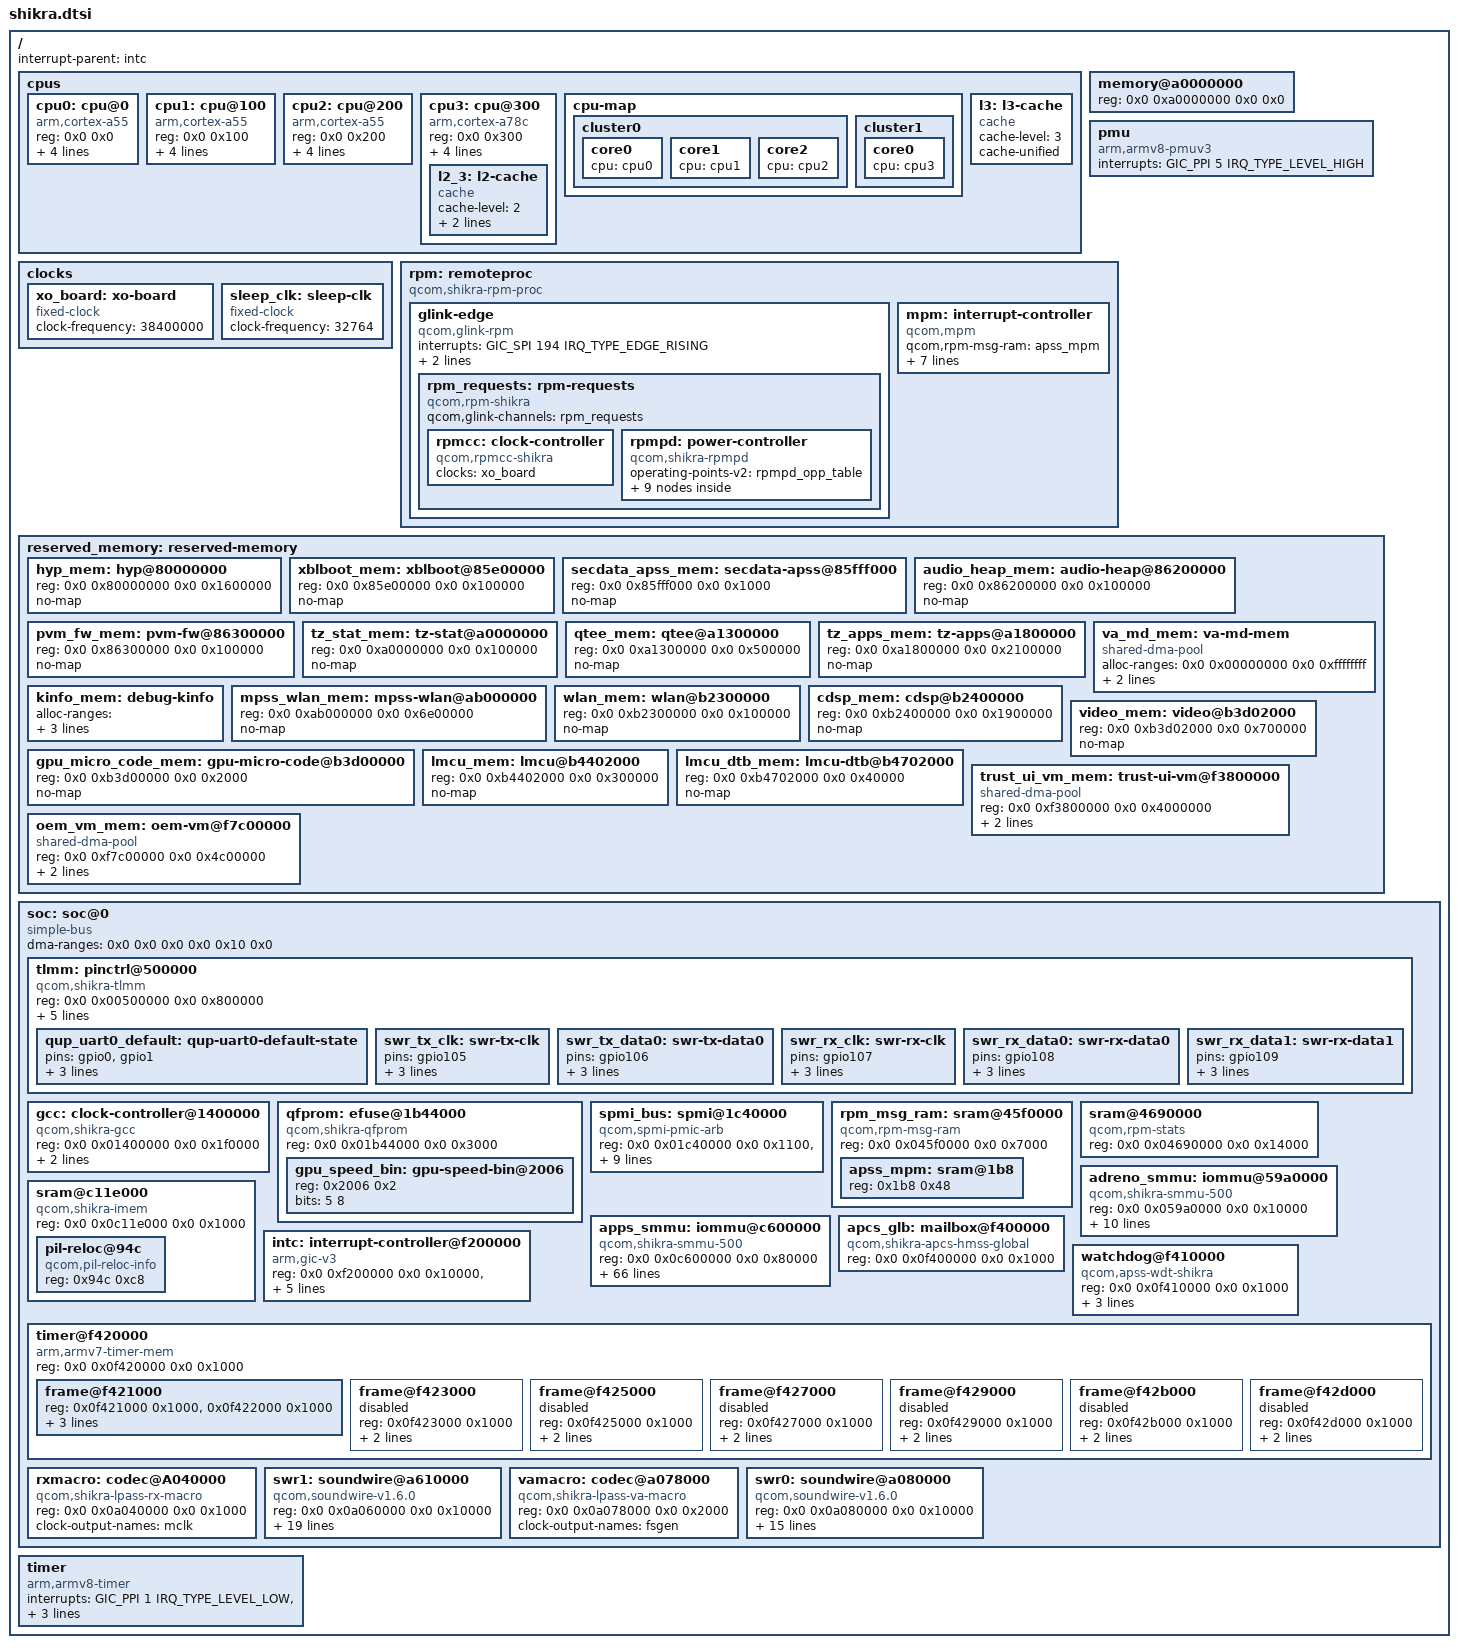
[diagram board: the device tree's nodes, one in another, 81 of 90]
// SPDX-License-Identifier: BSD-3-Clause
/*
 * Copyright (c) Qualcomm Technologies, Inc. and/or its subsidiaries.
 */

#include <dt-bindings/clock/qcom,rpmcc.h>
#include <dt-bindings/power/qcom-rpmpd.h>
#include <dt-bindings/clock/qcom,shikra-gcc.h>
#include <dt-bindings/interrupt-controller/arm-gic.h>
#include <dt-bindings/soc/qcom,gpr.h>
#include <dt-bindings/sound/qcom,q6dsp-lpass-ports.h>

/ {
	interrupt-parent = <&intc>;

	#address-cells = <2>;
	#size-cells = <2>;

	cpus {
		#address-cells = <2>;
		#size-cells = <0>;

		cpu0: cpu@0 {
			device_type = "cpu";
			compatible = "arm,cortex-a55";
			reg = <0x0 0x0>;
			enable-method = "psci";
			next-level-cache = <&l3>;
			capacity-dmips-mhz = <1024>;
			dynamic-power-coefficient = <100>;
		};

		cpu1: cpu@100 {
			device_type = "cpu";
			compatible = "arm,cortex-a55";
			reg = <0x0 0x100>;
			enable-method = "psci";
			next-level-cache = <&l3>;
			capacity-dmips-mhz = <1024>;
			dynamic-power-coefficient = <100>;
		};

		cpu2: cpu@200 {
			device_type = "cpu";
			compatible = "arm,cortex-a55";
			reg = <0x0 0x200>;
			enable-method = "psci";
			next-level-cache = <&l3>;
			capacity-dmips-mhz = <1024>;
			dynamic-power-coefficient = <100>;
		};

		cpu3: cpu@300 {
			device_type = "cpu";
			compatible = "arm,cortex-a78c";
			reg = <0x0 0x300>;
			enable-method = "psci";
			next-level-cache = <&l2_3>;
			capacity-dmips-mhz = <1946>;
			dynamic-power-coefficient = <486>;

			l2_3: l2-cache {
				compatible = "cache";
				cache-level = <2>;
				cache-unified;
				next-level-cache = <&l3>;
			};
		};

		cpu-map {
			cluster0 {
				core0 {
					cpu = <&cpu0>;
				};

				core1 {
					cpu = <&cpu1>;
				};

				core2 {
					cpu = <&cpu2>;
				};
			};

			cluster1 {
				core0 {
					cpu = <&cpu3>;
				};
			};
		};

		l3: l3-cache {
			compatible = "cache";
			cache-level = <3>;
			cache-unified;
		};
	};

	clocks {
		xo_board: xo-board {
			compatible = "fixed-clock";
			clock-frequency = <38400000>;
			#clock-cells = <0>;
		};

		sleep_clk: sleep-clk {
			compatible = "fixed-clock";
			clock-frequency = <32764>;
			#clock-cells = <0>;
		};
	};

	memory@a0000000 {
		device_type = "memory";
		/* We expect the bootloader to fill in the size */
		reg = <0x0 0xa0000000 0x0 0x0>;
	};

	pmu {
		compatible = "arm,armv8-pmuv3";
		interrupts = <GIC_PPI 5 IRQ_TYPE_LEVEL_HIGH>;
	};

	rpm: remoteproc {
		compatible = "qcom,shikra-rpm-proc", "qcom,rpm-proc";

		glink-edge {
			compatible = "qcom,glink-rpm";
			interrupts = <GIC_SPI 194 IRQ_TYPE_EDGE_RISING>;
			qcom,rpm-msg-ram = <&rpm_msg_ram>;
			mboxes = <&apcs_glb 0>;

			rpm_requests: rpm-requests {
				compatible = "qcom,rpm-shikra", "qcom,glink-smd-rpm";
				qcom,glink-channels = "rpm_requests";

				rpmcc: clock-controller {
					compatible = "qcom,rpmcc-shikra", "qcom,rpmcc";
					clocks = <&xo_board>;
					clock-names = "xo";
					#clock-cells = <1>;
				};

				rpmpd: power-controller {
					compatible = "qcom,shikra-rpmpd";
					#power-domain-cells = <1>;
					operating-points-v2 = <&rpmpd_opp_table>;

					rpmpd_opp_table: opp-table {
						compatible = "operating-points-v2";

						rpmpd_opp_min_svs: opp1 {
							opp-level = <RPM_SMD_LEVEL_MIN_SVS>;
						};

						rpmpd_opp_low_svs: opp2 {
							opp-level = <RPM_SMD_LEVEL_LOW_SVS>;
						};

						rpmpd_opp_svs: opp3 {
							opp-level = <RPM_SMD_LEVEL_SVS>;
						};

						rpmpd_opp_svs_plus: opp4 {
							opp-level = <RPM_SMD_LEVEL_SVS_PLUS>;
						};

						rpmpd_opp_nom: opp5 {
							opp-level = <RPM_SMD_LEVEL_NOM>;
						};

						rpmpd_opp_nom_plus: opp6 {
							opp-level = <RPM_SMD_LEVEL_NOM_PLUS>;
						};

						rpmpd_opp_turbo: opp7 {
							opp-level = <RPM_SMD_LEVEL_TURBO>;
						};

						rpmpd_opp_turbo_plus: opp8 {
							opp-level = <RPM_SMD_LEVEL_TURBO_NO_CPR>;
						};
					};
				};
			};
		};

		mpm: interrupt-controller {
			compatible = "qcom,mpm";
			qcom,rpm-msg-ram = <&apss_mpm>;
			interrupts = <GIC_SPI 197 IRQ_TYPE_EDGE_RISING>;
			mboxes = <&apcs_glb 1>;
			interrupt-controller;
			#interrupt-cells = <2>;
			#power-domain-cells = <0>;
			interrupt-parent = <&intc>;
			qcom,mpm-pin-count = <95>;
			qcom,mpm-pin-map = <2 275>,  /* TSENS0 uplow */
					   <12 422>, /* DWC3 ss_phy_irq */
					   <58 272>, /* QUSB2_PHY dmse_hv_vddmx */
					   <59 273>, /* QUSB2_PHY dpse_hv_vddmx */
					   <86 183>, /* MPM wake, SPMI */
					   <90 157>, /* QUSB2_PHY DM */
					   <91 158>; /* QUSB2_PHY DP */
		};
	};

	reserved_memory: reserved-memory {
		#address-cells = <2>;
		#size-cells = <2>;
		ranges;

		hyp_mem: hyp@80000000 {
			reg = <0x0 0x80000000 0x0 0x1600000>;
			no-map;
		};

		xblboot_mem: xblboot@85e00000 {
			reg = <0x0 0x85e00000 0x0 0x100000>;
			no-map;
		};

		secdata_apss_mem: secdata-apss@85fff000 {
			reg = <0x0 0x85fff000 0x0 0x1000>;
			no-map;
		};

		audio_heap_mem: audio-heap@86200000 {
			reg = <0x0 0x86200000 0x0 0x100000>;
			no-map;
		};

		pvm_fw_mem: pvm-fw@86300000 {
			reg = <0x0 0x86300000 0x0 0x100000>;
			no-map;
		};

		/* UEFI region at 0x9F400000 is reclaimed by Linux */
		tz_stat_mem: tz-stat@a0000000 {
			reg = <0x0 0xa0000000 0x0 0x100000>;
			no-map;
		};

		qtee_mem: qtee@a1300000 {
			reg = <0x0 0xa1300000 0x0 0x500000>;
			no-map;
		};

		tz_apps_mem: tz-apps@a1800000 {
			reg = <0x0 0xa1800000 0x0 0x2100000>;
			no-map;
		};

		va_md_mem: va-md-mem {
			compatible = "shared-dma-pool";
			alloc-ranges = <0x0 0x00000000 0x0 0xffffffff>;
			size = <0x0 0x1000000>;
			reusable;
		};

		kinfo_mem: debug-kinfo {
			alloc-ranges = <0x0 0x00000000 0xffffffff 0xffffffff>;
			size = <0x0 0x1000>;
			no-map;
		};

		mpss_wlan_mem: mpss-wlan@ab000000 {
			reg = <0x0 0xab000000 0x0 0x6e00000>;
			no-map;
		};

		wlan_mem: wlan@b2300000 {
			reg = <0x0 0xb2300000 0x0 0x100000>;
			no-map;
		};

		cdsp_mem: cdsp@b2400000 {
			reg = <0x0 0xb2400000 0x0 0x1900000>;
			no-map;
		};

		gpu_micro_code_mem: gpu-micro-code@b3d00000 {
			reg = <0x0 0xb3d00000 0x0 0x2000>;
			no-map;
		};

		video_mem: video@b3d02000 {
			reg = <0x0 0xb3d02000 0x0 0x700000>;
			no-map;
		};

		lmcu_mem: lmcu@b4402000 {
			reg = <0x0 0xb4402000 0x0 0x300000>;
			no-map;
		};

		lmcu_dtb_mem: lmcu-dtb@b4702000 {
			reg = <0x0 0xb4702000 0x0 0x40000>;
			no-map;
		};

		/* Linux kernel image is loaded at 0xB5000000 */
		trust_ui_vm_mem: trust-ui-vm@f3800000 {
			compatible = "shared-dma-pool";
			reg = <0x0 0xf3800000 0x0 0x4000000>;
			alignment = <0x0 0x400000>;
			reusable;
		};

		oem_vm_mem: oem-vm@f7c00000 {
			compatible = "shared-dma-pool";
			reg = <0x0 0xf7c00000 0x0 0x4c00000>;
			alignment = <0x0 0x400000>;
			reusable;
		};
	};

	soc: soc@0 {
		compatible = "simple-bus";

		#address-cells = <2>;
		#size-cells = <2>;
		dma-ranges = <0x0 0x0 0x0 0x0 0x10 0x0>;
		ranges = <0x0 0x0 0x0 0x0 0x10 0x0>;

		tlmm: pinctrl@500000 {
			compatible = "qcom,shikra-tlmm";
			reg = <0x0 0x00500000 0x0 0x800000>;

			interrupts = <GIC_SPI 227 IRQ_TYPE_LEVEL_HIGH>;

			gpio-controller;
			#gpio-cells = <2>;

			interrupt-controller;
			#interrupt-cells = <2>;

			gpio-ranges = <&tlmm 0 0 185>;
			wakeup-parent = <&mpm>;

			qup_uart0_default: qup-uart0-default-state {
				pins = "gpio0", "gpio1";
				function = "qup0_se1";
				drive-strength = <2>;
				bias-disable;
			};

			swr_tx_clk: swr-tx-clk {
				pins = "gpio105";
				function = "swr0_tx_clk";
				drive-strength = <10>;
				bias-disable;
			};

			swr_tx_data0: swr-tx-data0 {
				pins = "gpio106";
				function = "swr0_tx_data0";
				drive-strength = <10>;
				bias-bus-hold;
			};

			swr_rx_clk: swr-rx-clk {
				pins = "gpio107";
                                function = "swr0_rx_clk";
                                drive-strength = <10>;
                                bias-disable;
                        };

                        swr_rx_data0: swr-rx-data0 {
				pins = "gpio108";
                                function = "swr0_rx_data0";
                                drive-strength = <10>;
                                bias-bus-hold;
                        };

                        swr_rx_data1: swr-rx-data1 {
				pins = "gpio109";
                                function = "swr0_rx_data1";
                                drive-strength = <10>;
                                bias-bus-hold;
                        };
		};

		gcc: clock-controller@1400000 {
			compatible = "qcom,shikra-gcc";
			reg = <0x0 0x01400000 0x0 0x1f0000>;
			clocks = <&rpmcc RPM_SMD_XO_CLK_SRC>,
				 <&sleep_clk>,
				 <0>,
				 <0>,
				 <0>,
				 <0>,
				 <0>,
				 <0>;
			#clock-cells = <1>;
			#reset-cells = <1>;
			#power-domain-cells = <1>;
		};

		qfprom: efuse@1b44000 {
			compatible = "qcom,shikra-qfprom", "qcom,qfprom";
			reg = <0x0 0x01b44000 0x0 0x3000>;
			#address-cells = <1>;
			#size-cells = <1>;

			gpu_speed_bin: gpu-speed-bin@2006 {
				reg = <0x2006 0x2>;
				bits = <5 8>;
			};
		};

		spmi_bus: spmi@1c40000 {
			compatible = "qcom,spmi-pmic-arb";
			reg = <0x0 0x01c40000 0x0 0x1100>,
			      <0x0 0x01e00000 0x0 0x2000000>,
			      <0x0 0x03e00000 0x0 0x100000>,
			      <0x0 0x03f00000 0x0 0xa0000>,
			      <0x0 0x01c0a000 0x0 0x26000>;
			reg-names = "core",
				    "chnls",
				    "obsrvr",
				    "intr",
				    "cnfg";
			interrupts-extended = <&mpm 86 IRQ_TYPE_LEVEL_HIGH>;
			interrupt-names = "periph_irq";
			interrupt-controller;
			#interrupt-cells = <4>;
			#address-cells = <2>;
			#size-cells = <0>;
			qcom,channel = <0>;
			qcom,ee = <0>;
		};

		rpm_msg_ram: sram@45f0000 {
			compatible = "qcom,rpm-msg-ram", "mmio-sram";
			reg = <0x0 0x045f0000 0x0 0x7000>;

			#address-cells = <1>;
			#size-cells = <1>;
			ranges = <0 0x0 0x045f0000 0x7000>;

			apss_mpm: sram@1b8 {
				reg = <0x1b8 0x48>;
			};
		};

		sram@4690000 {
			compatible = "qcom,rpm-stats";
			reg = <0x0 0x04690000 0x0 0x14000>;
		};

		adreno_smmu: iommu@59a0000 {
			compatible = "qcom,shikra-smmu-500", "qcom,smmu-500", "arm,mmu-500";
			reg = <0x0 0x059a0000 0x0 0x10000>;
			#iommu-cells = <2>;
			#global-interrupts = <1>;

			interrupts = <GIC_SPI 163 IRQ_TYPE_LEVEL_HIGH>,
				     <GIC_SPI 167 IRQ_TYPE_LEVEL_HIGH>,
				     <GIC_SPI 168 IRQ_TYPE_LEVEL_HIGH>,
				     <GIC_SPI 169 IRQ_TYPE_LEVEL_HIGH>,
				     <GIC_SPI 170 IRQ_TYPE_LEVEL_HIGH>,
				     <GIC_SPI 171 IRQ_TYPE_LEVEL_HIGH>,
				     <GIC_SPI 172 IRQ_TYPE_LEVEL_HIGH>,
				     <GIC_SPI 173 IRQ_TYPE_LEVEL_HIGH>,
				     <GIC_SPI 174 IRQ_TYPE_LEVEL_HIGH>;
		};

		sram@c11e000 {
			compatible = "qcom,shikra-imem", "syscon", "simple-mfd";
			reg = <0x0 0x0c11e000 0x0 0x1000>;
			ranges = <0x0 0x0 0x0c11e000 0x1000>;

			#address-cells = <1>;
			#size-cells = <1>;

			pil-reloc@94c {
				compatible = "qcom,pil-reloc-info";
				reg = <0x94c 0xc8>;
			};
		};

		apps_smmu: iommu@c600000 {
			compatible = "qcom,shikra-smmu-500", "qcom,adreno-smmu",
				     "qcom,smmu-500", "arm,mmu-500";
			reg = <0x0 0x0c600000 0x0 0x80000>;
			#iommu-cells = <2>;
			#global-interrupts = <1>;

			interrupts = <GIC_SPI 81 IRQ_TYPE_LEVEL_HIGH>,
				     <GIC_SPI 87 IRQ_TYPE_LEVEL_HIGH>,
				     <GIC_SPI 88 IRQ_TYPE_LEVEL_HIGH>,
				     <GIC_SPI 89 IRQ_TYPE_LEVEL_HIGH>,
				     <GIC_SPI 90 IRQ_TYPE_LEVEL_HIGH>,
				     <GIC_SPI 91 IRQ_TYPE_LEVEL_HIGH>,
				     <GIC_SPI 92 IRQ_TYPE_LEVEL_HIGH>,
				     <GIC_SPI 93 IRQ_TYPE_LEVEL_HIGH>,
				     <GIC_SPI 94 IRQ_TYPE_LEVEL_HIGH>,
				     <GIC_SPI 95 IRQ_TYPE_LEVEL_HIGH>,
				     <GIC_SPI 96 IRQ_TYPE_LEVEL_HIGH>,
				     <GIC_SPI 97 IRQ_TYPE_LEVEL_HIGH>,
				     <GIC_SPI 98 IRQ_TYPE_LEVEL_HIGH>,
				     <GIC_SPI 99 IRQ_TYPE_LEVEL_HIGH>,
				     <GIC_SPI 100 IRQ_TYPE_LEVEL_HIGH>,
				     <GIC_SPI 101 IRQ_TYPE_LEVEL_HIGH>,
				     <GIC_SPI 102 IRQ_TYPE_LEVEL_HIGH>,
				     <GIC_SPI 103 IRQ_TYPE_LEVEL_HIGH>,
				     <GIC_SPI 104 IRQ_TYPE_LEVEL_HIGH>,
				     <GIC_SPI 105 IRQ_TYPE_LEVEL_HIGH>,
				     <GIC_SPI 106 IRQ_TYPE_LEVEL_HIGH>,
				     <GIC_SPI 107 IRQ_TYPE_LEVEL_HIGH>,
				     <GIC_SPI 108 IRQ_TYPE_LEVEL_HIGH>,
				     <GIC_SPI 109 IRQ_TYPE_LEVEL_HIGH>,
				     <GIC_SPI 110 IRQ_TYPE_LEVEL_HIGH>,
				     <GIC_SPI 111 IRQ_TYPE_LEVEL_HIGH>,
				     <GIC_SPI 112 IRQ_TYPE_LEVEL_HIGH>,
				     <GIC_SPI 113 IRQ_TYPE_LEVEL_HIGH>,
				     <GIC_SPI 114 IRQ_TYPE_LEVEL_HIGH>,
				     <GIC_SPI 115 IRQ_TYPE_LEVEL_HIGH>,
				     <GIC_SPI 116 IRQ_TYPE_LEVEL_HIGH>,
				     <GIC_SPI 117 IRQ_TYPE_LEVEL_HIGH>,
				     <GIC_SPI 118 IRQ_TYPE_LEVEL_HIGH>,
				     <GIC_SPI 119 IRQ_TYPE_LEVEL_HIGH>,
				     <GIC_SPI 120 IRQ_TYPE_LEVEL_HIGH>,
				     <GIC_SPI 121 IRQ_TYPE_LEVEL_HIGH>,
				     <GIC_SPI 122 IRQ_TYPE_LEVEL_HIGH>,
				     <GIC_SPI 123 IRQ_TYPE_LEVEL_HIGH>,
				     <GIC_SPI 124 IRQ_TYPE_LEVEL_HIGH>,
				     <GIC_SPI 125 IRQ_TYPE_LEVEL_HIGH>,
				     <GIC_SPI 126 IRQ_TYPE_LEVEL_HIGH>,
				     <GIC_SPI 127 IRQ_TYPE_LEVEL_HIGH>,
				     <GIC_SPI 128 IRQ_TYPE_LEVEL_HIGH>,
				     <GIC_SPI 129 IRQ_TYPE_LEVEL_HIGH>,
				     <GIC_SPI 130 IRQ_TYPE_LEVEL_HIGH>,
				     <GIC_SPI 131 IRQ_TYPE_LEVEL_HIGH>,
				     <GIC_SPI 132 IRQ_TYPE_LEVEL_HIGH>,
				     <GIC_SPI 133 IRQ_TYPE_LEVEL_HIGH>,
				     <GIC_SPI 134 IRQ_TYPE_LEVEL_HIGH>,
				     <GIC_SPI 135 IRQ_TYPE_LEVEL_HIGH>,
				     <GIC_SPI 136 IRQ_TYPE_LEVEL_HIGH>,
				     <GIC_SPI 137 IRQ_TYPE_LEVEL_HIGH>,
				     <GIC_SPI 138 IRQ_TYPE_LEVEL_HIGH>,
				     <GIC_SPI 139 IRQ_TYPE_LEVEL_HIGH>,
				     <GIC_SPI 140 IRQ_TYPE_LEVEL_HIGH>,
				     <GIC_SPI 141 IRQ_TYPE_LEVEL_HIGH>,
				     <GIC_SPI 142 IRQ_TYPE_LEVEL_HIGH>,
				     <GIC_SPI 143 IRQ_TYPE_LEVEL_HIGH>,
				     <GIC_SPI 144 IRQ_TYPE_LEVEL_HIGH>,
				     <GIC_SPI 145 IRQ_TYPE_LEVEL_HIGH>,
				     <GIC_SPI 146 IRQ_TYPE_LEVEL_HIGH>,
				     <GIC_SPI 147 IRQ_TYPE_LEVEL_HIGH>,
				     <GIC_SPI 148 IRQ_TYPE_LEVEL_HIGH>,
				     <GIC_SPI 149 IRQ_TYPE_LEVEL_HIGH>,
				     <GIC_SPI 150 IRQ_TYPE_LEVEL_HIGH>;
		};

		intc: interrupt-controller@f200000 {
			compatible = "arm,gic-v3";
			reg = <0x0 0xf200000 0x0 0x10000>, /* GICD */
			      <0x0 0xf240000 0x0 0x80000>; /* GICR * 4 regions */

			interrupts = <GIC_PPI 8 IRQ_TYPE_LEVEL_HIGH>;

			#interrupt-cells = <3>;
			interrupt-controller;

			#redistributor-regions = <1>;
			redistributor-stride = <0x0 0x20000>;

			#address-cells = <2>;
			#size-cells = <2>;
			ranges;
		};

		apcs_glb: mailbox@f400000 {
			compatible = "qcom,shikra-apcs-hmss-global";
			reg = <0x0 0x0f400000 0x0 0x1000>;
			#mbox-cells = <1>;
		};

		watchdog@f410000 {
			compatible = "qcom,apss-wdt-shikra", "qcom,kpss-wdt";
			reg = <0x0 0x0f410000 0x0 0x1000>;
			interrupts = <GIC_SPI 0 IRQ_TYPE_LEVEL_HIGH>,
				     <GIC_SPI 1 IRQ_TYPE_LEVEL_HIGH>;
			clocks = <&sleep_clk>;
		};

		timer@f420000 {
			compatible = "arm,armv7-timer-mem";
			reg = <0x0 0x0f420000  0x0 0x1000>;

			#address-cells = <1>;
			#size-cells = <1>;
			ranges = <0x0 0x0 0x0 0x10000000>;

			frame@f421000 {
				reg = <0x0f421000 0x1000>,
				      <0x0f422000 0x1000>;
				frame-number = <0>;
				interrupts = <GIC_SPI 8 IRQ_TYPE_LEVEL_HIGH>,
					     <GIC_SPI 6 IRQ_TYPE_LEVEL_HIGH>;
			};

			frame@f423000 {
				reg = <0x0f423000 0x1000>;
				frame-number = <1>;
				interrupts = <GIC_SPI 9 IRQ_TYPE_LEVEL_HIGH>;
				status = "disabled";
			};

			frame@f425000 {
				reg = <0x0f425000 0x1000>;
				frame-number = <2>;
				interrupts = <GIC_SPI 10 IRQ_TYPE_LEVEL_HIGH>;
				status = "disabled";
			};

			frame@f427000 {
				reg = <0x0f427000 0x1000>;
				frame-number = <3>;
				interrupts = <GIC_SPI 11 IRQ_TYPE_LEVEL_HIGH>;
				status = "disabled";
			};

			frame@f429000 {
				reg = <0x0f429000 0x1000>;
				frame-number = <4>;
				interrupts = <GIC_SPI 12 IRQ_TYPE_LEVEL_HIGH>;
				status = "disabled";
			};

			frame@f42b000 {
				reg = <0x0f42b000 0x1000>;
				frame-number = <5>;
				interrupts = <GIC_SPI 13 IRQ_TYPE_LEVEL_HIGH>;
				status = "disabled";
			};

			frame@f42d000 {
				reg = <0x0f42d000 0x1000>;
				frame-number = <6>;
				interrupts = <GIC_SPI 14 IRQ_TYPE_LEVEL_HIGH>;
				status = "disabled";
			};
		};


		rxmacro: codec@A040000 {
			compatible = "qcom,shikra-lpass-rx-macro";
			reg = <0x0 0x0a040000 0x0 0x1000>;

			/* TODO: once Gpr and prm enbled enble below clocks */
			//clocks = <&q6prmcc LPASS_CLK_ID_RX_CORE_MCLK LPASS_CLK_ATTRIBUTE_COUPLE_NO>,
			//	 <&q6prmcc LPASS_CLK_ID_RX_CORE_NPL_MCLK LPASS_CLK_ATTRIBUTE_COUPLE_NO>,
			//	 <&q6prmcc LPASS_HW_DCODEC_VOTE LPASS_CLK_ATTRIBUTE_COUPLE_NO>,
			//	 <&vamacro>;
			//clock-names = "mclk",
			//	      "npl",
			//	      "dcodec",
			//	      "fsgen";
			#clock-cells = <0>;
			clock-output-names = "mclk";
			#sound-dai-cells = <1>;
		};

		swr1: soundwire@a610000 {
			compatible = "qcom,soundwire-v1.6.0";
			reg = <0x0 0x0a060000 0x0 0x10000>;
			interrupts = <GIC_SPI 330 IRQ_TYPE_LEVEL_HIGH>;

			clocks = <&rxmacro>;
			clock-names = "iface";

			label = "RX";
			qcom,din-ports = <0>;
			qcom,dout-ports = <5>;

			qcom,ports-sinterval-low =	/bits/ 8 <0x03 0x1f 0x1f 0x07 0x00>;
			qcom,ports-offset1 =		/bits/ 8 <0x00 0x00 0x0b 0x01 0x00>;
			qcom,ports-offset2 =		/bits/ 8 <0x00 0x00 0x0b 0x00 0x00>;
			qcom,ports-hstart =		/bits/ 8 <0xff 0x03 0xff 0xff 0xff>;
			qcom,ports-hstop =		/bits/ 8 <0xff 0x06 0xff 0xff 0xff>;
			qcom,ports-word-length =	/bits/ 8 <0x01 0x07 0x04 0xff 0xff>;
			qcom,ports-block-pack-mode =	/bits/ 8 <0xff 0x00 0x01 0xff 0xff>;
			qcom,ports-block-group-count =	/bits/ 8 <0xff 0xff 0xff 0xff 0x00>;
			qcom,ports-lane-control =	/bits/ 8 <0x01 0x00 0x00 0x00 0x00>;

			#sound-dai-cells = <1>;
			#address-cells = <2>;
			#size-cells = <0>;
		};


		vamacro: codec@a078000 {
			compatible = "qcom,shikra-lpass-va-macro";
			reg = <0x0 0x0a078000 0x0 0x2000>;

			/* TODO: once Gpr and prm enbled enble below clocks */
			//clocks = <&q6prmcc LPASS_CLK_ID_TX_CORE_MCLK LPASS_CLK_ATTRIBUTE_COUPLE_NO>,
			//	 <&q6prmcc LPASS_HW_DCODEC_VOTE LPASS_CLK_ATTRIBUTE_COUPLE_NO>,
			//	 <&q6prmcc LPASS_CLK_ID_TX_CORE_NPL_MCLK LPASS_CLK_ATTRIBUTE_COUPLE_NO>;
			//clock-names = "mclk",
			//	      "dcodec",
			//	      "npl";
			#clock-cells = <0>;
			clock-output-names = "fsgen";
			#sound-dai-cells = <1>;
		};

		swr0: soundwire@a080000 {
			compatible = "qcom,soundwire-v1.6.0";
			reg = <0x0 0x0a080000 0x0 0x10000>;
			interrupts = <GIC_SPI 328 IRQ_TYPE_LEVEL_HIGH>,
				     <GIC_SPI 406 IRQ_TYPE_LEVEL_HIGH>;
			clocks = <&vamacro>;
			clock-names = "iface";

			label = "VA_TX";
			qcom,din-ports = <3>;
			qcom,dout-ports = <0>;

			qcom,ports-sinterval-low =	/bits/ 8 <0x03 0x03 0x03>;
			qcom,ports-offset1 =		/bits/ 8 <0x01 0x02 0x01>;
			qcom,ports-offset2 =		/bits/ 8 <0x00 0x00 0x00>;
			qcom,ports-hstart =		/bits/ 8 <0xff 0xff 0xff>;
			qcom,ports-hstop =		/bits/ 8 <0xff 0xff 0xff>;
			qcom,ports-word-length =	/bits/ 8 <0xff 0xff 0xff>;
			qcom,ports-block-pack-mode =	/bits/ 8 <0xff 0xff 0xff>;
			qcom,ports-block-group-count =	/bits/ 8 <0xff 0xff 0xff>;
			qcom,ports-lane-control =	/bits/ 8 <0x00 0x00 0x00>;

			#sound-dai-cells = <1>;
			#address-cells = <2>;
			#size-cells = <0>;
		};
	};

	timer {
		compatible = "arm,armv8-timer";

		interrupts = <GIC_PPI 1 IRQ_TYPE_LEVEL_LOW>,
			     <GIC_PPI 2 IRQ_TYPE_LEVEL_LOW>,
			     <GIC_PPI 3 IRQ_TYPE_LEVEL_LOW>,
			     <GIC_PPI 0 IRQ_TYPE_LEVEL_LOW>;
	};
};
